VERSION "2.0"

NS_ :

BS_:

BU_: Gateway Body_ECU Engine_ECU Transmission_ECU Brake_ECU Steering_ECU

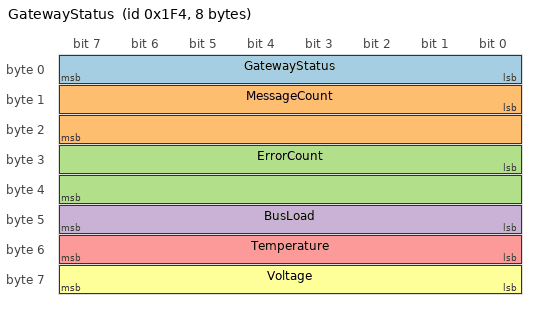
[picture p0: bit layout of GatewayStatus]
BO_ 500 GatewayStatus: 8 Gateway
 SG_ GatewayStatus : 0|8@1+ (1,0) [0|255] "" Gateway
 SG_ MessageCount : 8|16@1+ (1,0) [0|65535] "" Gateway
 SG_ ErrorCount : 24|16@1+ (1,0) [0|65535] "" Gateway
 SG_ BusLoad : 40|8@1+ (0.392157,0) [0|100] "%" Gateway
 SG_ Temperature : 48|8@1+ (1,-40) [-40|215] "degC" Gateway
 SG_ Voltage : 56|8@1+ (0.1,10) [10|15.5] "V" Gateway

BO_ 600 MultiplexedData: 8 Body_ECU
 SG_ Multiplexor : 0|4@1+ (1,0) [0|15] "" Body_ECU
 SG_ Temperature1 m0 : 8|8@1+ (1,-40) [-40|215] "degC" Body_ECU
 SG_ Temperature2 m0 : 16|8@1+ (1,-40) [-40|215] "degC" Body_ECU
 SG_ Temperature3 m0 : 24|8@1+ (1,-40) [-40|215] "degC" Body_ECU
 SG_ Temperature4 m0 : 32|8@1+ (1,-40) [-40|215] "degC" Body_ECU
 SG_ Pressure1 m1 : 8|16@1+ (0.01,0) [0|655.35] "kPa" Body_ECU
 SG_ Pressure2 m1 : 24|16@1+ (0.01,0) [0|655.35] "kPa" Body_ECU
 SG_ Pressure3 m1 : 40|16@1+ (0.01,0) [0|655.35] "kPa" Body_ECU
 SG_ Pressure4 m1 : 56|16@1+ (0.01,0) [0|655.35] "kPa" Body_ECU
 SG_ Speed1 m2 : 8|16@1+ (0.00390625,0) [0|255.996] "km/h" Body_ECU
 SG_ Speed2 m2 : 24|16@1+ (0.00390625,0) [0|255.996] "km/h" Body_ECU
 SG_ Speed3 m2 : 40|16@1+ (0.00390625,0) [0|255.996] "km/h" Body_ECU
 SG_ Speed4 m2 : 56|16@1+ (0.00390625,0) [0|255.996] "km/h" Body_ECU

BO_ 700 ExtendedEngineData: 8 Engine_ECU
 SG_ EngineRPM : 0|16@1+ (0.125,0) [0|8031.875] "rpm" Engine_ECU
 SG_ EngineTorque : 16|16@1+ (0.1,-3276.8) [-3276.8|3276.7] "Nm" Engine_ECU
 SG_ FuelConsumption : 32|16@1+ (0.01,0) [0|655.35] "L/100km" Engine_ECU
 SG_ AirFuelRatio : 48|16@1+ (0.01,0) [0|655.35] "" Engine_ECU
 SG_ TurboBoost : 56|8@1+ (0.1,0) [0|25.5] "bar" Engine_ECU

BO_ 800 BrakeSystemData: 6 Brake_ECU
 SG_ BrakePressure_FL : 0|16@1+ (0.01,0) [0|655.35] "bar" Brake_ECU
 SG_ BrakePressure_FR : 16|16@1+ (0.01,0) [0|655.35] "bar" Brake_ECU
 SG_ BrakePressure_RL : 32|16@1+ (0.01,0) [0|655.35] "bar" Brake_ECU
 SG_ BrakePressure_RR : 48|16@1+ (0.01,0) [0|655.35] "bar" Brake_ECU

BO_ 900 SteeringData: 4 Steering_ECU
 SG_ SteeringAngle : 0|16@1+ (0.1,-3276.8) [-3276.8|3276.7] "deg" Steering_ECU
 SG_ SteeringTorque : 16|16@1+ (0.1,-3276.8) [-3276.8|3276.7] "Nm" Steering_ECU
 SG_ SteeringSpeed : 32|16@1+ (0.1,-3276.8) [-3276.8|3276.7] "deg/s" Steering_ECU

CM_ "Gateway status information";
CM_ BO_ 500 "Gateway status message";
CM_ SG_ 500 GatewayStatus "Gateway operational status";

VAL_TABLE_ GatewayStatus 0 "Offline" 1 "Online" 2 "Error" 3 "Maintenance" ;

VAL_TABLE_ Multiplexor 0 "Temperature" 1 "Pressure" 2 "Speed" ;

BA_DEF_ "BusType" STRING ;
BA_DEF_ "NetworkManagement" ENUM "Yes","No" ;
BA_DEF_DEF_ "BusType" "CAN" ;
BA_DEF_DEF_ "NetworkManagement" "No" ;
BA_ "NetworkManagement" "Yes" ;
